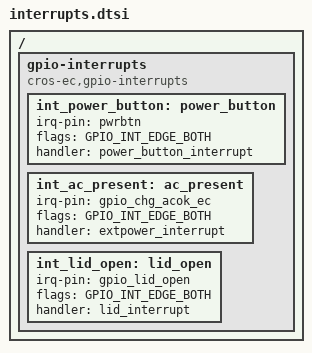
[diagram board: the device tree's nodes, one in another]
/* Copyright 2024 The ChromiumOS Authors
 * Use of this source code is governed by a BSD-style license that can be
 * found in the LICENSE file.
 */

/ {
	gpio-interrupts {
		compatible = "cros-ec,gpio-interrupts";

		int_power_button: power_button {
			irq-pin = <&pwrbtn>;
			flags = <GPIO_INT_EDGE_BOTH>;
			handler = "power_button_interrupt";
		};
		int_ac_present: ac_present {
			irq-pin = <&gpio_chg_acok_ec>;
			flags = <GPIO_INT_EDGE_BOTH>;
			handler = "extpower_interrupt";
		};
		int_lid_open: lid_open {
			irq-pin = <&gpio_lid_open>;
			flags = <GPIO_INT_EDGE_BOTH>;
			handler = "lid_interrupt";
		};
	};
};
